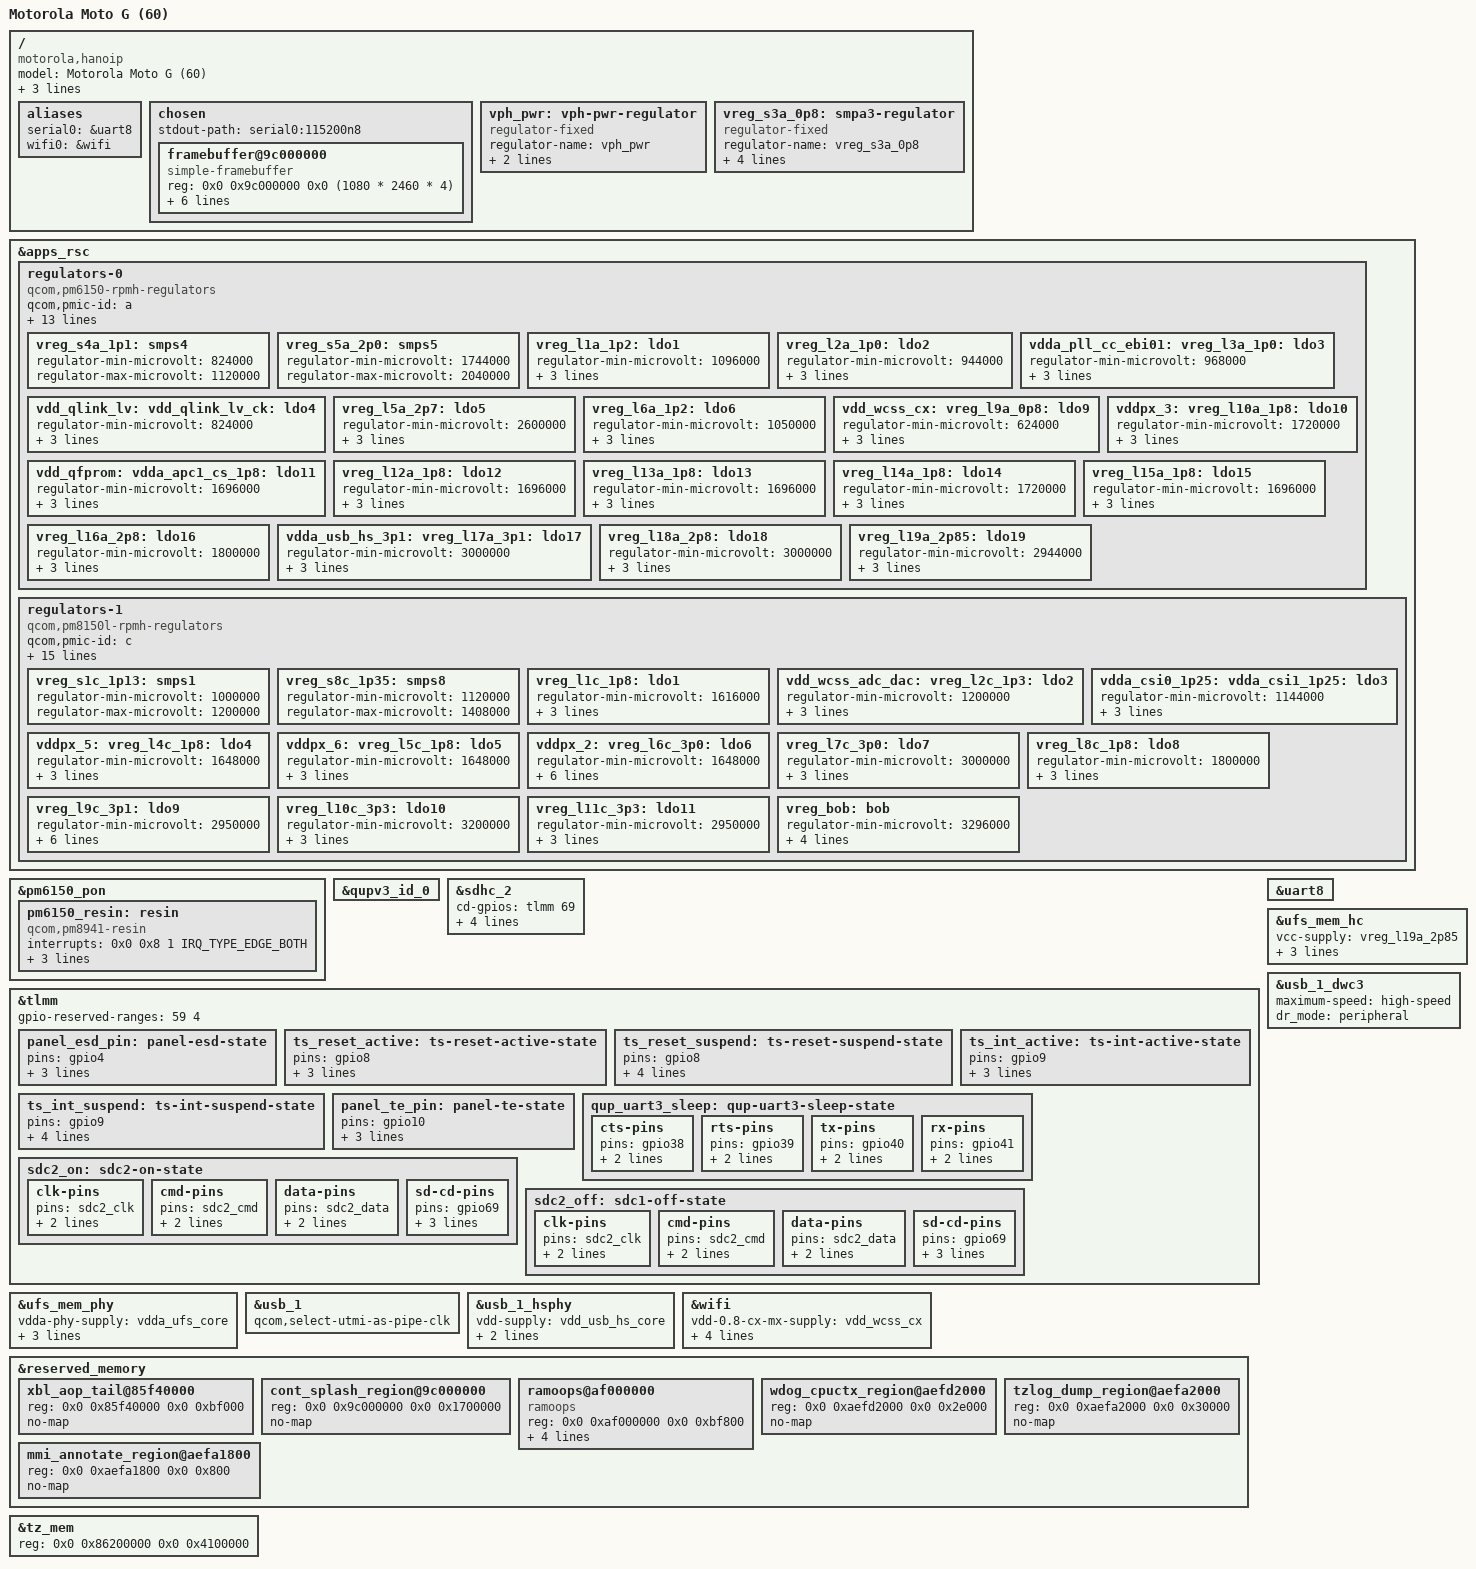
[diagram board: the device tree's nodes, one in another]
// SPDX-License-Identifier: GPL-2.0-only
/*
 * Motorola Moto G (60) - hanoip (XT2135-1), SM7150
 *
 * Board description for the postmarketOS mainline port.
 *
 * Identity, framebuffer and reserved-memory map come from the stock
 * downstream DTB (docs/device-info/running.dts). Peripheral wiring is taken
 * from sm7150-xiaomi-common.dtsi, with supplies confirmed by phandle against
 * the downstream DTB: UFS (L19A, L12A), Wi-Fi WCN3990 (L1C, L2C, L10C, L11C),
 * SD card (L9C, L6C, cd on GPIO 69).
 *
 * Based on the hanoip stub of sm7150-mainline (fuyukihidekii).
 */

/dts-v1/;

#include <dt-bindings/arm/qcom,ids.h>
#include <dt-bindings/firmware/qcom,scm.h>
#include <dt-bindings/gpio/gpio.h>
#include <dt-bindings/input/input.h>
#include <dt-bindings/pinctrl/qcom,pmic-gpio.h>
#include <dt-bindings/regulator/qcom,rpmh-regulator.h>

#include "sm7150.dtsi"
#include "pm6150.dtsi"
#include "pm8150l.dtsi"

/ {
	model = "Motorola Moto G (60)";
	compatible = "motorola,hanoip", "qcom,sm7150";
	chassis-type = "handset";

	qcom,msm-id = <QCOM_ID_SM7150 0>;
	qcom,board-id = <0x4c 0xb200>;

	aliases {
		serial0 = &uart8;
		wifi0 = &wifi;
	};

	chosen {
		stdout-path = "serial0:115200n8";
		#address-cells = <2>;
		#size-cells = <2>;
		ranges;

		framebuffer@9c000000 {
			compatible = "simple-framebuffer";
			reg = <0x0 0x9c000000 0x0 (1080 * 2460 * 4)>;
			width = <1080>;
			height = <2460>;
			stride = <(1080 * 4)>;
			format = "a8r8g8b8";
			clocks = <&gcc GCC_DISP_HF_AXI_CLK>,
				 <&gcc GCC_DISP_SF_AXI_CLK>;
		};
	};

	vph_pwr: vph-pwr-regulator {
		compatible = "regulator-fixed";
		regulator-name = "vph_pwr";
		regulator-min-microvolt = <3700000>;
		regulator-max-microvolt = <3700000>;
	};

	// S3A is really mx.lvl but it's there for supply map completeness sake.
	vreg_s3a_0p8: smpa3-regulator {
		compatible = "regulator-fixed";
		regulator-name = "vreg_s3a_0p8";

		regulator-min-microvolt = <800000>;
		regulator-max-microvolt = <800000>;
		regulator-always-on;
		vin-supply = <&vph_pwr>;
	};
};

&apps_rsc {
	regulators-0 {
		compatible = "qcom,pm6150-rpmh-regulators";
		qcom,pmic-id = "a";

		vdd-s1-supply = <&vph_pwr>;
		vdd-s2-supply = <&vph_pwr>;
		vdd-s3-supply = <&vph_pwr>;
		vdd-s4-supply = <&vph_pwr>;
		vdd-s5-supply = <&vph_pwr>;

		vdd-l1-supply = <&vreg_s8c_1p35>;
		vdd-l2-l3-supply = <&vreg_s4a_1p1>;
		vdd-l4-l7-l8-supply = <&vreg_s4a_1p1>;
		vdd-l5-l16-l17-l18-l19-supply = <&vreg_bob>;
		vdd-l6-supply = <&vreg_s8c_1p35>;
		vdd-l9-supply = <&vreg_s3a_0p8>;
		vdd-l10-l14-l15-supply = <&vreg_s5a_2p0>;
		vdd-l11-l12-l13-supply = <&vreg_s5a_2p0>;

		/*
		 * S1 are unused.
		 * S2-S3, L7-L8 are ARCs:
		 * S2 - gfx.lvl,
		 * S3 - mx.lvl,
		 * L7 - lmx.lvl,
		 * L8 - lcx.lvl.
		 */

		vreg_s4a_1p1: smps4 {
			regulator-min-microvolt = <824000>;
			regulator-max-microvolt = <1120000>;
		};

		vreg_s5a_2p0: smps5 {
			regulator-min-microvolt = <1744000>;
			regulator-max-microvolt = <2040000>;
		};

		vreg_l1a_1p2: ldo1 {
			regulator-min-microvolt = <1096000>;
			regulator-max-microvolt = <1304000>;
			regulator-initial-mode = <RPMH_REGULATOR_MODE_HPM>;
		};

		vreg_l2a_1p0: ldo2 {
			regulator-min-microvolt = <944000>;
			regulator-max-microvolt = <1056000>;
			regulator-initial-mode = <RPMH_REGULATOR_MODE_HPM>;
		};

		vdda_pll_cc_ebi01:
		vreg_l3a_1p0: ldo3 {
			regulator-min-microvolt = <968000>;
			regulator-max-microvolt = <1064000>;
			regulator-initial-mode = <RPMH_REGULATOR_MODE_HPM>;
		};

		vdd_qlink_lv:
		vdd_qlink_lv_ck:
		vdd_usb_hs_core:
		vdda_mipi_csi0_0p9:
		vdda_mipi_csi1_0p9:
		vdda_mipi_csi2_0p9:
		vdda_mipi_csi3_0p9:
		vdda_mipi_dsi0_pll:
		vdda_mipi_dsi1_pll:
		vdda_qrefs_0p9:
		vdda_ufs_core:
		vdda_usb_ss_dp_core:
		vreg_l4a_0p88: ldo4 {
			regulator-min-microvolt = <824000>;
			regulator-max-microvolt = <920000>;
			regulator-initial-mode = <RPMH_REGULATOR_MODE_HPM>;
		};

		vreg_l5a_2p7: ldo5 {
			regulator-min-microvolt = <2600000>;
			regulator-max-microvolt = <2800000>;
			regulator-initial-mode = <RPMH_REGULATOR_MODE_HPM>;
		};

		vreg_l6a_1p2: ldo6 {
			regulator-min-microvolt = <1050000>;
			regulator-max-microvolt = <1304000>;
			regulator-initial-mode = <RPMH_REGULATOR_MODE_HPM>;
		};

		vdd_wcss_cx:
		vreg_l9a_0p8: ldo9 {
			regulator-min-microvolt = <624000>;
			regulator-max-microvolt = <760000>;
			regulator-initial-mode = <RPMH_REGULATOR_MODE_HPM>;
		};

		vddpx_3:
		vreg_l10a_1p8: ldo10 {
			regulator-min-microvolt = <1720000>;
			regulator-max-microvolt = <1832000>;
			regulator-initial-mode = <RPMH_REGULATOR_MODE_HPM>;
		};

		vdd_qfprom:
		vdda_apc1_cs_1p8:
		vdda_qrefs_1p8:
		vdda_usb_hs_1p8:
		vddpx_11:
		vreg_l11a_1p8: ldo11 {
			regulator-min-microvolt = <1696000>;
			regulator-max-microvolt = <1984000>;
			regulator-initial-mode = <RPMH_REGULATOR_MODE_HPM>;
		};

		vreg_l12a_1p8: ldo12 {
			regulator-min-microvolt = <1696000>;
			regulator-max-microvolt = <1952000>;
			regulator-initial-mode = <RPMH_REGULATOR_MODE_HPM>;
		};

		vreg_l13a_1p8: ldo13 {
			regulator-min-microvolt = <1696000>;
			regulator-max-microvolt = <1904000>;
			regulator-initial-mode = <RPMH_REGULATOR_MODE_HPM>;
		};

		vreg_l14a_1p8: ldo14 {
			regulator-min-microvolt = <1720000>;
			regulator-max-microvolt = <1856000>;
			regulator-initial-mode = <RPMH_REGULATOR_MODE_HPM>;
		};

		vreg_l15a_1p8: ldo15 {
			regulator-min-microvolt = <1696000>;
			regulator-max-microvolt = <1904000>;
			regulator-initial-mode = <RPMH_REGULATOR_MODE_HPM>;
		};

		vreg_l16a_2p8: ldo16 {
			regulator-min-microvolt = <1800000>;
			regulator-max-microvolt = <1800000>;
			regulator-initial-mode = <RPMH_REGULATOR_MODE_HPM>;
		};

		vdda_usb_hs_3p1:
		vreg_l17a_3p1: ldo17 {
			regulator-min-microvolt = <3000000>;
			regulator-max-microvolt = <3232000>;
			regulator-initial-mode = <RPMH_REGULATOR_MODE_HPM>;
		};

		vreg_l18a_2p8: ldo18 {
			regulator-min-microvolt = <3000000>;
			regulator-max-microvolt = <3000000>;
			regulator-initial-mode = <RPMH_REGULATOR_MODE_HPM>;
		};

		vreg_l19a_2p85: ldo19 {
			regulator-min-microvolt = <2944000>;
			regulator-max-microvolt = <3304000>;
			regulator-initial-mode = <RPMH_REGULATOR_MODE_HPM>;
		};
	};

	regulators-1 {
		compatible = "qcom,pm8150l-rpmh-regulators";
		qcom,pmic-id = "c";

		vdd-s1-supply = <&vph_pwr>;
		vdd-s2-supply = <&vph_pwr>;
		vdd-s3-supply = <&vph_pwr>;
		vdd-s4-supply = <&vph_pwr>;
		vdd-s5-supply = <&vph_pwr>;
		vdd-s6-supply = <&vph_pwr>;
		vdd-s7-supply = <&vph_pwr>;
		vdd-s8-supply = <&vph_pwr>;

		/*
		 * There should be:
		 * vdd-l1-l8-supply = <&vreg_s5a_2p0>;
		 * But pm7150l doesn't have access to S5A.
		 */
		vdd-l2-l3-supply = <&vreg_s8c_1p35>;
		vdd-l4-l5-l6-supply = <&vreg_bob>;
		vdd-l7-l11-supply = <&vreg_bob>;
		vdd-l9-l10-supply = <&vreg_bob>;

		vdd-bob-supply = <&vph_pwr>;
		vdd-flash-supply = <&vreg_bob>;
		vdd-rgb-supply = <&vreg_bob>;

		/*
		 * S4, S5 are unused.
		 * S2, S3, S7 are ARCs:
		 * S2-S3 - cx.lvl,
		 * S7 - mss.lvl.
		 */

		vreg_s1c_1p13: smps1 {
			regulator-min-microvolt = <1000000>;
			regulator-max-microvolt = <1200000>;
		};

		vreg_s8c_1p35: smps8 {
			regulator-min-microvolt = <1120000>;
			regulator-max-microvolt = <1408000>;
		};

		vreg_l1c_1p8: ldo1 {
			regulator-min-microvolt = <1616000>;
			regulator-max-microvolt = <1984000>;
			regulator-initial-mode = <RPMH_REGULATOR_MODE_HPM>;
		};

		vdd_wcss_adc_dac:
		vreg_l2c_1p3: ldo2 {
			regulator-min-microvolt = <1200000>;
			regulator-max-microvolt = <1352000>;
			regulator-initial-mode = <RPMH_REGULATOR_MODE_HPM>;
		};

		vdda_csi0_1p25:
		vdda_csi1_1p25:
		vdda_csi2_1p25:
		vdda_csi3_1p25:
		vdda_hv_ebi0:
		vdda_mipi_dsi0_1p2:
		vdda_mipi_dsi1_1p2:
		vdda_ufs_1p2:
		vdda_usb_ss_dp_1p2:
		vddpx_10:
		vreg_l3c_1p23: ldo3 {
			regulator-min-microvolt = <1144000>;
			regulator-max-microvolt = <1256000>;
			regulator-initial-mode = <RPMH_REGULATOR_MODE_HPM>;
		};

		vddpx_5:
		vreg_l4c_1p8: ldo4 {
			regulator-min-microvolt = <1648000>;
			regulator-max-microvolt = <2950000>;
			regulator-initial-mode = <RPMH_REGULATOR_MODE_HPM>;
		};

		vddpx_6:
		vreg_l5c_1p8: ldo5 {
			regulator-min-microvolt = <1648000>;
			regulator-max-microvolt = <2950000>;
			regulator-initial-mode = <RPMH_REGULATOR_MODE_HPM>;
		};

		vddpx_2:
		vreg_l6c_3p0: ldo6 {
			regulator-min-microvolt = <1648000>;
			regulator-max-microvolt = <3100000>;
			regulator-initial-mode = <RPMH_REGULATOR_MODE_HPM>;
			regulator-allow-set-load;
			regulator-allowed-modes = <RPMH_REGULATOR_MODE_LPM
						   RPMH_REGULATOR_MODE_HPM>;
		};

		vreg_l7c_3p0: ldo7 {
			regulator-min-microvolt = <3000000>;
			regulator-max-microvolt = <3312000>;
			regulator-initial-mode = <RPMH_REGULATOR_MODE_HPM>;
		};

		vreg_l8c_1p8: ldo8 {
			regulator-min-microvolt = <1800000>;
			regulator-max-microvolt = <1900000>;
			regulator-initial-mode = <RPMH_REGULATOR_MODE_HPM>;
		};

		/*
		 * Downstream specifies a range of 2950-3312mV.
		 * Tighten the range to 2950-3100mV.
		 */
		vreg_l9c_3p1: ldo9 {
			regulator-min-microvolt = <2950000>;
			regulator-max-microvolt = <3100000>;
			regulator-initial-mode = <RPMH_REGULATOR_MODE_HPM>;
			regulator-allow-set-load;
			regulator-allowed-modes = <RPMH_REGULATOR_MODE_LPM
						   RPMH_REGULATOR_MODE_HPM>;
		};

		vreg_l10c_3p3: ldo10 {
			regulator-min-microvolt = <3200000>;
			regulator-max-microvolt = <3312000>;
			regulator-initial-mode = <RPMH_REGULATOR_MODE_HPM>;
		};

		vreg_l11c_3p3: ldo11 {
			regulator-min-microvolt = <2950000>;
			regulator-max-microvolt = <3400000>;
			regulator-initial-mode = <RPMH_REGULATOR_MODE_HPM>;
		};

		vreg_bob: bob {
			regulator-min-microvolt = <3296000>;
			regulator-max-microvolt = <3960000>;
			regulator-initial-mode = <RPMH_REGULATOR_MODE_AUTO>;
			regulator-allow-bypass;
		};
	};
};

&pm6150_pon {
	pm6150_resin: resin {
		compatible = "qcom,pm8941-resin";
		interrupts = <0x0 0x8 1 IRQ_TYPE_EDGE_BOTH>;
		debounce = <15625>;
		bias-pull-up;
		linux,code = <KEY_VOLUMEDOWN>;
	};
};

&qupv3_id_0 {
	status = "okay";
};

&sdhc_2 {
	cd-gpios = <&tlmm 69 GPIO_ACTIVE_HIGH>;

	vmmc-supply = <&vreg_l9c_3p1>;
	vqmmc-supply = <&vreg_l6c_3p0>;

	pinctrl-names = "default", "sleep";
	pinctrl-0 = <&sdc2_on>;
	pinctrl-1 = <&sdc2_off>;
	status = "okay";
};

&tlmm {
	gpio-reserved-ranges = <59 4>;

	panel_esd_pin: panel-esd-state {
		pins = "gpio4";
		function = "gpio";
		drive-strength = <2>;
		bias-pull-down;
	};

	ts_reset_active: ts-reset-active-state {
		pins = "gpio8";
		function = "gpio";
		drive-strength = <16>;
		bias-pull-up;
	};

	ts_reset_suspend: ts-reset-suspend-state {
		pins = "gpio8";
		function = "gpio";
		drive-strength = <16>;
		bias-disable;
		output-high;
	};

	ts_int_active: ts-int-active-state {
		pins = "gpio9";
		function = "gpio";
		drive-strength = <16>;
		bias-pull-up;
	};

	ts_int_suspend: ts-int-suspend-state {
		pins = "gpio9";
		function = "gpio";
		drive-strength = <16>;
		input-enable;
		bias-disable;
	};

	panel_te_pin: panel-te-state {
		pins = "gpio10";
		function = "mdp_vsync";
		drive-strength = <2>;
		bias-pull-down;
	};

	qup_uart3_sleep: qup-uart3-sleep-state {
		cts-pins {
			pins = "gpio38";
			function = "gpio";
			bias-pull-down;
		};

		rts-pins {
			pins = "gpio39";
			function = "gpio";
			bias-pull-down;
		};

		tx-pins {
			pins = "gpio40";
			function = "gpio";
			bias-pull-up;
		};

		rx-pins {
			pins = "gpio41";
			function = "gpio";
			bias-pull-up;
		};
	};

	sdc2_on: sdc2-on-state {
		clk-pins {
			pins = "sdc2_clk";
			bias-disable;
			drive-strength = <16>;
		};

		cmd-pins {
			pins = "sdc2_cmd";
			bias-pull-up;
			drive-strength = <10>;
		};

		data-pins {
			pins = "sdc2_data";
			bias-pull-up;
			drive-strength = <10>;
		};

		sd-cd-pins {
			pins = "gpio69";
			function = "gpio";
			bias-pull-up;
			drive-strength = <2>;
		};
	};

	sdc2_off: sdc1-off-state {
		clk-pins {
			pins = "sdc2_clk";
			bias-disable;
			drive-strength = <2>;
		};

		cmd-pins {
			pins = "sdc2_cmd";
			bias-pull-up;
			drive-strength = <2>;
		};

		data-pins {
			pins = "sdc2_data";
			bias-pull-up;
			drive-strength = <2>;
		};

		sd-cd-pins {
			pins = "gpio69";
			function = "gpio";
			bias-pull-up;
			drive-strength = <2>;
		};
	};
};

&uart8 {
	status = "okay";
};

&ufs_mem_hc {
	vcc-supply = <&vreg_l19a_2p85>;
	vcc-max-microamp = <600000>;
	vccq2-supply = <&vreg_l12a_1p8>;
	vccq2-max-microamp = <600000>;
	status = "okay";
};

&ufs_mem_phy {
	vdda-phy-supply = <&vdda_ufs_core>;
	vdda-pll-supply = <&vdda_ufs_1p2>;
	vdda-phy-max-microamp = <62900>;
	vdda-pll-max-microamp = <18300>;
	status = "okay";
};

&usb_1 {
	qcom,select-utmi-as-pipe-clk;
	status = "okay";
};

&usb_1_dwc3 {
	maximum-speed = "high-speed";
	dr_mode = "peripheral";
	status = "okay";
};

&usb_1_hsphy {
	vdd-supply = <&vdd_usb_hs_core>;
	vdda-pll-supply = <&vdda_usb_hs_1p8>;
	vdda-phy-dpdm-supply = <&vdda_usb_hs_3p1>;
	status = "okay";
};

&wifi {
	vdd-0.8-cx-mx-supply = <&vdd_wcss_cx>;
	vdd-1.8-xo-supply = <&vreg_l1c_1p8>;
	vdd-1.3-rfa-supply = <&vdd_wcss_adc_dac>;
	vdd-3.3-ch0-supply = <&vreg_l10c_3p3>;
	vdd-3.3-ch1-supply = <&vreg_l11c_3p3>;
	status = "okay";
};

/*
 * Regions below come from the stock DTB. The upstream reserved_memory node
 * already provides the shared labels (smem_mem, adsp_mem, ...) referenced by
 * sm7150.dtsi, so only the device-specific differences are added here.
 */
&reserved_memory {
	/*
	 * Stock xbl_aop_mem spans 0x85e00000-0x85fff000, but the upstream xbl,
	 * aop and aop-cmd-db nodes stop at 0x85f40000. Reserve the rest so Linux
	 * never touches XBL/AOP memory (would trigger an XPU violation reset).
	 */
	xbl_aop_tail@85f40000 {
		reg = <0x0 0x85f40000 0x0 0xbf000>;
		no-map;
	};

	cont_splash_region@9c000000 {
		reg = <0x0 0x9c000000 0x0 0x1700000>;
		no-map;
	};

	ramoops@af000000 {
		compatible = "ramoops";
		reg = <0x0 0xaf000000 0x0 0xbf800>;
		console-size = <0x40000>;
		pmsg-size = <0x40000>;
		record-size = <0x3f800>;
		no-dump-oops;
	};

	wdog_cpuctx_region@aefd2000 {
		reg = <0x0 0xaefd2000 0x0 0x2e000>;
		no-map;
	};

	tzlog_dump_region@aefa2000 {
		reg = <0x0 0xaefa2000 0x0 0x30000>;
		no-map;
	};

	mmi_annotate_region@aefa1800 {
		reg = <0x0 0xaefa1800 0x0 0x800>;
		no-map;
	};
};

&tz_mem {
	reg = <0x0 0x86200000 0x0 0x4100000>;
};
